# DA1469x register map
Vendor: Dialog; Series: DA1469x; File version: 1.2
CPU: CM33 r1p0, little endian, no MPU, FPU, 3 interrupt priority bits
Registers are 32-bit, read-write, reset 0x0 unless marked. A register's access mark holds for its fields unless they carry their own. Offsets are from the block's base; [hi:lo] are bit positions; {n}, {i} and the like mark numbered series.

## UART — UART registers
Base 0x50020000
0x00 UART_RBR_THR_DLL_REG — Receive Buffer Register
  [7:0] RBR_THR_DLL — Receive Buffer Register: (RBR). This register contains the data byte received on the serial input port (sin) in UART mode or the serial infrared input (sir_in) in infrared mode. The data in this register is valid only if the Data Ready (DR) bit in the Line status Register (LSR) is set. If FIFOs are disabled (FCR[0] set to zero), the data in the RBR must be read before the next data arrives, otherwise it will be overwritten, resulting in an overrun error. If FIFOs are enabled (FCR[0] set to one), this register accesses the head of the receive FIFO. If the receive FIFO is full and this register is not read before the next data character arrives, then the data already in the FIFO will be preserved but any incoming data will be lost. An overrun error will also occur. Transmit Holding Register: (THR) This register contains data to be transmitted on the serial output port (sout) in UART mode or the serial infrared output (sir_out_n) in infrared mode. Data should only be written to the THR when the THR Empty (THRE) bit (LSR[5]) is set. If FIFO's are disabled (FCR[0] set to zero) and THRE is set, writing a single character to the THR clears the THRE. Any additional writes to the THR before the THRE is set again causes the THR data to be overwritten. If FIFO's are enabled (FCR[0] set to one) and THRE is set, x number of characters of data may be written to the THR before the FIFO is full. The number x (default=16) is determined by the value of FIFO Depth that you set during configuration. Any attempt to write data when the FIFO is full results in the write data being lost. Divisor Latch (Low): (DLL) This register makes up the lower 8-bits of a 16-bit, read/write, Divisor Latch register that contains the baud rate divisor for the UART. This register may only be accessed when the DLAB bit (LCR[7]) is set. The output baud rate is equal to the serial clock (sclk) frequency divided by sixteen times the value of the baud rate divisor, as follows: baud rate = (serial clock freq) / (16 * divisor) Note that with the Divisor Latch Registers (DLL and DLH) set to zero, the baud clock is disabled and no serial communications will occur. Also, once the DLL is set, at least 8 clock cycles of the slowest DW_apb_uart clock should be allowed to pass before transmitting or receiving data. Divisor Latch (High): (DLH) (Note: This register is placed in UART_IER_DLH_REG with offset 0x4) Upper 8-bits of a 16-bit, read/write, Divisor Latch register that contains the baud rate divisor for the UART. This register may be accessed only when the DLAB bit (LCR[7]) is set. The output baud rate is equal to the serial clock frequency divided by sixteen times the value of the baud rate divisor, as follows: baud rate = (serial clock freq) / (16 * divisor). Note that with the Divisor Latch Registers (DLL and DLH) set to zero, the baud clock is disabled and no serial communications occur. Also, once the DLH is set, at least 8 clock cycles of the slowest DW_apb_uart clock should be allowed to pass before transmitting or receiving data.
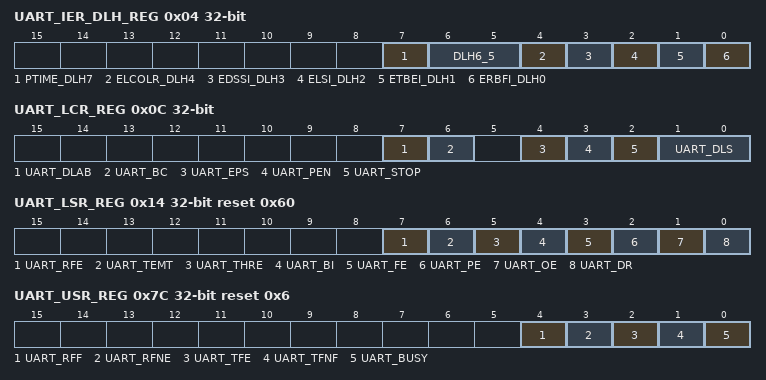
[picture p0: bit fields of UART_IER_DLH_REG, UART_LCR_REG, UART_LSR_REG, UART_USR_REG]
0x04 UART_IER_DLH_REG — Interrupt Enable Register
  [7] PTIME_DLH7 — Interrupt Enable Register: PTIME, Programmable THRE Interrupt Mode Enable. This is used to enable/disable the generation of THRE Interrupt. 0 = disabled 1 = enabled Divisor Latch (High): Bit[7] of the 8 bit DLH register.
  [6:5] DLH6_5 — Divisor Latch (High): Bit[6:5] of the 8 bit DLH register
  [4] ELCOLR_DLH4 — Interrupt Enable Register: (read only) ELCOLR, this bit controls the method for clearing the status in the LSR register. This is applicable only for Overrun Error, Parity Error, Framing Error, and Break Interrupt status bits. Always 0 = LSR status bits are cleared either on reading Rx FIFO (RBR Read) or On reading LSR register. Divisor Latch (High): Bit[4] of the 8 bit DLH register
  [3] EDSSI_DLH3 — Interrupt Enable Register: reserved Divisor Latch (High): Bit[3] of the 8 bit DLH register
  [2] ELSI_DLH2 — Interrupt Enable Register: ELSI, Enable Receiver Line Status Interrupt. This is used to enable/disable the generation of Receiver Line Status Interrupt. This is the highest priority interrupt. 0 = disabled 1 = enabled Divisor Latch (High): Bit[2] of the 8 bit DLH register.
  [1] ETBEI_DLH1 — Interrupt Enable Register: ETBEI, Enable Transmit Holding Register Empty Interrupt. This is used to enable/disable the generation of Transmitter Holding Register Empty Interrupt. This is the third highest priority interrupt. 0 = disabled 1 = enabled Divisor Latch (High): Bit[1] of the 8 bit DLH register.
  [0] ERBFI_DLH0 — Interrupt Enable Register: ERBFI, Enable Received Data Available Interrupt. This is used to enable/disable the generation of Received Data Available Interrupt and the Character Timeout Interrupt (if in FIFO mode and FIFO's enabled). These are the second highest priority interrupts. 0 = disabled 1 = enabled Divisor Latch (High): Bit[0] of the 8 bit DLH register.
0x08 UART_IIR_FCR_REG reset 0x1 — Interrupt Identification Register/FIFO Control Register
  [7:0] IIR_FCR — On Read Interrupt Identification Register : Bits[7:6], FIFO's Enabled (or FIFOSE): This is used to indicate whether the FIFO's are enabled or disabled. 00 = disabled. 11 = enabled. Bits[5:4],Reserved Bits[3:0], Interrupt ID (or IID): This indicates the highest priority pending interrupt which can be one of the following types: 0001 = no interrupt pending. 0010 = THR empty. 0100 = received data available. 0110 = receiver line status. 0111 = busy detect. 1100 = character timeout. On Write FIFO Control Register Bits[7:6], RCVR Trigger (or RT):. This is used to select the trigger level in the receiver FIFO at which the Received Data Available Interrupt will be generated. In auto flow control mode it is used to determine when the rts_n signal will be de-asserted. It also determines when the dma_rx_req_n signal will be asserted when in certain modes of operation. The following trigger levels are supported: 00 = 1 character in the FIFO 01 = FIFO 1/4 full 10 = FIFO 1/2 full 11 = FIFO 2 less than full Bits[5:4], TX Empty Trigger (or TET): This is used to select the empty threshold level at which the THRE Interrupts will be generated when the mode is active. It also determines when the dma_tx_req_n signal will be asserted when in certain modes of operation. The following trigger levels are supported: 00 = FIFO empty 01 = 2 characters in the FIFO 10 = FIFO 1/4 full 11 = FIFO 1/2 full Bit[3], DMA Mode (or DMAM): This determines the DMA signalling mode used for the dma_tx_req_n and dma_rx_req_n output signals. 0 = mode 0 1 = mode 1 Bit[2], XMIT FIFO Reset (or XFIFOR): This resets the control portion of the transmit FIFO and treats the FIFO as empty. Note that this bit is 'self-clearing' and it is not necessary to clear this bit. Bit[1], RCVR FIFO Reset (or RFIFOR): This resets the control portion of the receive FIFO and treats the FIFO as empty. Note that this bit is 'self-clearing' and it is not necessary to clear this bit. Bit[0], FIFO Enable (or FIFOE): This enables/disables the transmit (XMIT) and receive (RCVR) FIFO's. Whenever the value of this bit is changed both the XMIT and RCVR controller portion of FIFO's will be reset.
0x0C UART_LCR_REG — Line Control Register
  [7] UART_DLAB — Divisor Latch Access Bit. This bit is used to enable reading and writing of the Divisor Latch register (DLL and DLH) to set the baud rate of the UART. This bit must be cleared after initial baud rate setup in order to access other registers.
  [6] UART_BC — Break Control Bit. This is used to cause a break condition to be transmitted to the receiving device. If set to one the serial output is forced to the spacing (logic 0) state. When not in Loopback Mode, as determined by MCR[4], the sout line is forced low until the Break bit is cleared.
  [4] UART_EPS — Even Parity Select. Writeable only when UART is not busy (USR[0] is zero). This is used to select between even and odd parity, when parity is enabled (PEN set to one). If set to one, an even number of logic 1s is transmitted or checked. If set to zero, an odd number of logic 1s is transmitted or checked.
  [3] UART_PEN — Parity Enable. Writeable only when UART is not busy (USR[0] is zero) This bit is used to enable and disable parity generation and detection in transmitted and received serial character respectively. 0 = parity disabled 1 = parity enabled
  [2] UART_STOP — Number of stop bits. This is used to select the number of stop bits per character that the peripheral transmits and receives. If set to zero, one stop bit is transmitted in the serial data. If set to one and the data bits are set to 5 (LCR[1:0] set to zero) one and a half stop bits is transmitted. Otherwise, two stop bits are transmitted. Note that regardless of the number of stop bits selected, the receiver checks only the first stop bit. 0 = 1 stop bit 1 = 1.5 stop bits when DLS (LCR[1:0]) is zero, else 2 stop bit
  [1:0] UART_DLS — Data Length Select. This is used to select the number of data bits per character that the peripheral transmits and receives. The number of bit that may be selected areas follows: 00 = 5 bits 01 = 6 bits 10 = 7 bits 11 = 8 bits
0x10 UART_MCR_REG — Modem Control Register
  [4] UART_LB — LoopBack Bit. This is used to put the UART into a diagnostic mode for test purposes. If operating in UART mode (SIR_MODE not active, MCR[6] set to zero), data on the sout line is held high, while serial data output is looped back to the sin line, internally. In this mode all the interrupts are fully functional. Also, in loopback mode, the modem control inputs (dsr_n, cts_n, ri_n, dcd_n) are disconnected and the modem control outputs (dtr_n, rts_n, out1_n, out2_n) are looped back to the inputs, internally. If operating in infrared mode (SIR_MODE active, MCR[6] set to one), data on the sir_out_n line is held low, while serial data output is inverted and looped back to the sir_in line.
0x14 UART_LSR_REG reset 0x60 — Line Status Register
  [7] UART_RFE ro — Receiver FIFO Error bit. This bit is only relevant when FIFOs are enabled (FCR[0] set to one). This is used to indicate if there is at least one parity error, framing error, or break indication in the FIFO. 0 = no error in RX FIFO 1 = error in RX FIFO This bit is cleared when the LSR is read and the character with the error is at the top of the receiver FIFO and there are no subsequent errors in the FIFO.
  [6] UART_TEMT ro — Transmitter Empty bit. If FIFOs enabled (FCR[0] set to one), this bit is set whenever the Transmitter Shift Register and the FIFO are both empty. If FIFOs are disabled, this bit is set whenever the Transmitter Holding Register and the Transmitter Shift Register are both empty.
  [5] UART_THRE ro — Transmit Holding Register Empty bit. If THRE mode is disabled (IER[7] set to zero) and regardless of FIFO's being implemented/enabled or not, this bit indicates that the THR or TX FIFO is empty. This bit is set whenever data is transferred from the THR or TX FIFO to the transmitter shift register and no new data has been written to the THR or TX FIFO. This also causes a THRE Interrupt to occur, if the THRE Interrupt is enabled. If both modes are active (IER[7] set to one and FCR[0] set to one respectively), the functionality is switched to indicate the transmitter FIFO is full, and no longer controls THRE interrupts, which are then controlled by the FCR[5:4] threshold setting.
  [4] UART_BI ro — Break Interrupt bit. This is used to indicate the detection of a break sequence on the serial input data. It is set whenever the serial input, sin, is held in a logic '0' state for longer than the sum of start time + data bits + parity + stop bits. In the FIFO mode, the character associated with the break condition is carried through the FIFO and is revealed when the character is at the top of the FIFO. Reading the LSR clears the BI bit. In the non-FIFO mode, the BI indication occurs immediately and persists until the LSR is read.
  [3] UART_FE ro — Framing Error bit. This is used to indicate the occurrence of a framing error in the receiver. A framing error occurs when the receiver does not detect a valid STOP bit in the received data. In the FIFO mode, since the framing error is associated with a character received, it is revealed when the character with the framing error is at the top of the FIFO. When a framing error occurs, the UART tries to resynchronize. It does this by assuming that the error was due to the start bit of the next character and then continues receiving the other bit i.e. data, and/or parity and stop. It should be noted that the Framing Error (FE) bit (LSR[3]) is set if a break interrupt has occurred, as indicated by Break Interrupt (BI) bit (LSR[4]). 0 = no framing error 1 = framing error Reading the LSR clears the FE bit.
  [2] UART_PE ro — Parity Error bit. This is used to indicate the occurrence of a parity error in the receiver if the Parity Enable (PEN) bit (LCR[3]) is set. In the FIFO mode, since the parity error is associated with a character received, it is revealed when the character with the parity error arrives at the top of the FIFO. It should be noted that the Parity Error (PE) bit (LSR[2]) is set if a break interrupt has occurred, as indicated by Break Interrupt (BI) bit (LSR[4]). 0 = no parity error 1 = parity error Reading the LSR clears the PE bit.
  [1] UART_OE ro — Overrun error bit. This is used to indicate the occurrence of an overrun error. This occurs if a new data character was received before the previous data was read. In the non-FIFO mode, the OE bit is set when a new character arrives in the receiver before the previous character was read from the RBR. When this happens, the data in the RBR is overwritten. In the FIFO mode, an overrun error occurs when the FIFO is full and a new character arrives at the receiver. The data in the FIFO is retained and the data in the receive shift register is lost. 0 = no overrun error 1 = overrun error Reading the LSR clears the OE bit.
  [0] UART_DR ro — Data Ready bit. This is used to indicate that the receiver contains at least one character in the RBR or the receiver FIFO. 0 = no data ready 1 = data ready This bit is cleared when the RBR is read in non-FIFO mode, or when the receiver FIFO is empty, in FIFO mode.
0x1C UART_SCR_REG — Scratchpad Register
  [7:0] UART_SCRATCH_PAD — This register is for programmers to use as a temporary storage space. It has no defined purpose in the UART Ctrl.
{0x30+4i} UART_SRBR_STHR{i}_REG (i=0..15) — Shadow Receive/Transmit Buffer Register
  [7:0] SRBR_STHRx — Shadow Receive Buffer Register x: This is a shadow register for the RBR and has been allocated sixteen 32-bit locations so as to accommodate burst accesses from the master. This register contains the data byte received on the serial input port (sin) in UART mode or the serial infrared input (sir_in) in infrared mode. The data in this register is valid only if the Data Ready (DR) bit in the Line status Register (LSR) is set. If FIFOs are disabled (FCR[0] set to zero), the data in the RBR must be read before the next data arrives, otherwise it will be overwritten, resulting in an overrun error. If FIFOs are enabled (FCR[0] set to one), this register accesses the head of the receive FIFO. If the receive FIFO is full and this register is not read before the next data character arrives, then the data already in the FIFO will be preserved but any incoming data will be lost. An overrun error will also occur. Shadow Transmit Holding Register 0: This is a shadow register for the THR and has been allocated sixteen 32-bit locations so as to accommodate burst accesses from the master. This register contains data to be transmitted on the serial output port (sout) in UART mode or the serial infrared output (sir_out_n) in infrared mode. Data should only be written to the THR when the THR Empty (THRE) bit (LSR[5]) is set. If FIFO's are disabled (FCR[0] set to zero) and THRE is set, writing a single character to the THR clears the THRE. Any additional writes to the THR before the THRE is set again causes the THR data to be overwritten. If FIFO's are enabled (FCR[0] set to one) and THRE is set, x number of characters of data may be written to the THR before the FIFO is full. The number x (default=16) is determined by the value of FIFO Depth that you set during configuration. Any attempt to write data when the FIFO is full results in the write data being lost.
0x7C UART_USR_REG reset 0x6 — UART Status register.
  [4] UART_RFF ro — Receive FIFO Full. This is used to indicate that the receive FIFO is completely full. 0 = Receive FIFO not full 1 = Receive FIFO Full This bit is cleared when the RX FIFO is no longer full.
  [3] UART_RFNE ro — Receive FIFO Not Empty. This is used to indicate that the receive FIFO contains one or more entries. 0 = Receive FIFO is empty 1 = Receive FIFO is not empty This bit is cleared when the RX FIFO is empty.
  [2] UART_TFE ro — Transmit FIFO Empty. This is used to indicate that the transmit FIFO is completely empty. 0 = Transmit FIFO is not empty 1 = Transmit FIFO is empty This bit is cleared when the TX FIFO is no longer empty.
  [1] UART_TFNF ro — Transmit FIFO Not Full. This is used to indicate that the transmit FIFO in not full. 0 = Transmit FIFO is full 1 = Transmit FIFO is not full This bit is cleared when the TX FIFO is full.
  [0] UART_BUSY ro — UART Busy. This indicates that a serial transfer is in progress, when cleared indicates that the uart is idle or inactive. 0 = uart is idle or inactive 1 =uart is busy (actively transferring data) Note that it is possible for the UART Busy bit to be cleared even though a new character may have been sent from another device. That is, if the uart has no data in the THR and RBR and there is no transmission in progress and a start bit of a new character has just reached the uart. This is due to the fact that a valid start is not seen until the middle of the bit period and this duration is dependent on the baud divisor that has been programmed. If a second system clock has been implemented (CLOCK_MODE == Enabled) the assertion of this bit will also be delayed by several cycles of the slower clock.
0x80 UART_TFL_REG — Transmit FIFO Level
  [4:0] UART_TRANSMIT_FIFO_LEVEL ro — Transmit FIFO Level. This is indicates the number of data entries in the transmit FIFO.
0x84 UART_RFL_REG — Receive FIFO Level.
  [4:0] UART_RECEIVE_FIFO_LEVEL ro — Receive FIFO Level. This is indicates the number of data entries in the receive FIFO.
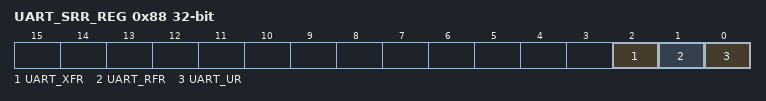
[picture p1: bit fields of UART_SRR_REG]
0x88 UART_SRR_REG — Software Reset Register.
  [2] UART_XFR wo — XMIT FIFO Reset. This is a shadow register for the XMIT FIFO Reset bit (FCR[2]). This can be used to remove the burden on software having to store previously written FCR values (which are pretty static) just to reset the transmit FIFO. This resets the control portion of the transmit FIFO and treats the FIFO as empty. Note that this bit is 'self-clearing'. It is not necessary to clear this bit.
  [1] UART_RFR wo — RCVR FIFO Reset. This is a shadow register for the RCVR FIFO Reset bit (FCR[1]). This can be used to remove the burden on software having to store previously written FCR values (which are pretty static) just to reset the receive FIFO This resets the control portion of the receive FIFO and treats the FIFO as empty. Note that this bit is 'self-clearing'. It is not necessary to clear this bit.
  [0] UART_UR wo — UART Reset. This asynchronously resets the UART Ctrl and synchronously removes the reset assertion. For a two clock implementation both pclk and sclk domains are reset.
0x90 UART_SBCR_REG — Shadow Break Control Register
  [0] UART_SHADOW_BREAK_CONTROL — Shadow Break Control Bit. This is a shadow register for the Break bit (LCR[6]), this can be used to remove the burden of having to performing a read modify write on the LCR. This is used to cause a break condition to be transmitted to the receiving device. If set to one the serial output is forced to the spacing (logic 0) state. When not in Loopback Mode, as determined by MCR[4], the sout line is forced low until the Break bit is cleared.
0x94 UART_SDMAM_REG — Shadow DMA Mode
  [0] UART_SHADOW_DMA_MODE — Shadow DMA Mode. This is a shadow register for the DMA mode bit (FCR[3]). This can be used to remove the burden of having to store the previously written value to the FCR in memory and having to mask this value so that only the DMA Mode bit gets updated. This determines the DMA signalling mode used for the dma_tx_req_n and dma_rx_req_n output signals. 0 = mode 0 1 = mode 1
0x98 UART_SFE_REG — Shadow FIFO Enable
  [0] UART_SHADOW_FIFO_ENABLE — Shadow FIFO Enable. This is a shadow register for the FIFO enable bit (FCR[0]). This can be used to remove the burden of having to store the previously written value to the FCR in memory and having to mask this value so that only the FIFO enable bit gets updated.This enables/disables the transmit (XMIT) and receive (RCVR) FIFOs. If this bit is set to zero (disabled) after being enabled then both the XMIT and RCVR controller portion of FIFOs are reset.
0x9C UART_SRT_REG — Shadow RCVR Trigger
  [1:0] UART_SHADOW_RCVR_TRIGGER — Shadow RCVR Trigger. This is a shadow register for the RCVR trigger bits (FCR[7:6]). This can be used to remove the burden of having to store the previously written value to the FCR in memory and having to mask this value so that only the RCVR trigger bit gets updated. This is used to select the trigger level in the receiver FIFO at which the Received Data Available Interrupt is generated. It also determines when the dma_rx_req_n signal is asserted when DMA Mode (FCR[3]) = 1. The following trigger levels are supported: 00 = 1 character in the FIFO 01 = FIFO ¼ full 10 = FIFO ½ full 11 = FIFO 2 less than full
0xA0 UART_STET_REG — Shadow TX Empty Trigger
  [1:0] UART_SHADOW_TX_EMPTY_TRIGGER — Shadow TX Empty Trigger. This is a shadow register for the TX empty trigger bits (FCR[5:4]). This can be used to remove the burden of having to store the previously written value to the FCR in memory and having to mask this value so that only the TX empty trigger bit gets updated. This is used to select the empty threshold level at which the THRE Interrupts are generated when the mode is active. The following trigger levels are supported: 00 = FIFO empty 01 = 2 characters in the FIFO 10 = FIFO ¼ full 11 = FIFO ½ full
0xA4 UART_HTX_REG — Halt TX
  [0] UART_HALT_TX — This register is use to halt transmissions, so that the transmit FIFO can be filled by the master when FIFOs are implemented and enabled. 0 = Halt TX disabled 1 = Halt TX enabled Note, if FIFOs are not enabled, the setting of the halt TX register has no effect on operation.
0xA8 UART_DMASA_REG — DMA Software Acknowledge
  [0] UART_DMASA wo — This register is use to perform DMA software acknowledge if a transfer needs to be terminated due to an error condition. For example, if the DMA disables the channel, then the DW_apb_uart should clear its request. This will cause the TX request, TX single, RX request and RX single signals to de-assert. Note that this bit is 'self-clearing' and it is not necessary to clear this bit.
0xC0 UART_DLF_REG — Divisor Latch Fraction Register
  [3:0] UART_DLF — The fractional value is added to integer value set by DLH, DLL. Fractional value is equal UART_DLF/16
0xF8 UART_UCV_REG reset 0x3430312A (reset mask 0x7FFFFFFF) — Component Version
  [31:0] UART_UCV ro
0xFC UART_CTR_REG reset 0x44570110 (reset mask 0x7FFFFFFF) — Component Type Register
  [31:0] UART_CTR ro
